# R9A02G021 register map
Vendor: Renesas Electronics Corporation; Series: RISC-V; File version: 1.10.00 + 202304131714_CPU
CPU: other r0p0, little endian, no MPU, no FPU, VTOR, 4 interrupt priority bits, 32 interrupts
Registers are 8-bit, read-write, reset 0x0 unless marked. A register's access mark holds for its fields unless they carry their own. Offsets are from the block's base; [hi:lo] are bit positions; {n}, {i} and the like mark numbered series; <NAME> marks a mode.

## IICA — Serial Interface IICA
Base 0x40093000
{0x0+0x100*i} IICA{i} (i=0..1) — IICA Shift Register {i}
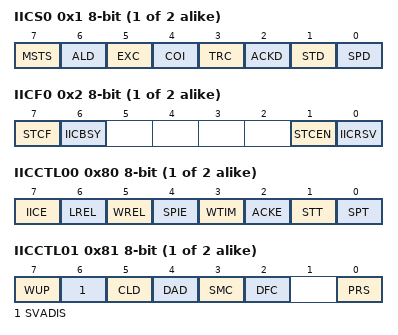
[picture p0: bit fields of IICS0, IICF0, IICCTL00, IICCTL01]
{0x1+0x100*i} IICS{i} (i=0..1) ro — IICA Status Register {i}
  [7] MSTS — Master status check flag
    0=Slave device status or communication standby status; 1=Master device communication status
  [6] ALD — Detection of arbitration loss
    0=This status means either that there was no arbitration, or that the arbitration result was a win; 1=This status indicates the arbitration result was a loss. The MSTS bit is cleared.
  [5] EXC — Detection of extension code reception
    0=Extension code was not received; 1=Extension code was received. Or, the all address match function is enabled.
  [4] COI — Detection of matching addresses
    0=Addresses do not match; 1=Addresses match. Or, the all address match function is enabled.
  [3] TRC — Detection of transmit and receive status
    0=Receive status (other than transmit status). The SDAAn line is set for high impedance.; 1=Transmit status. The value in the SOn latch is enabled for output to the SDAAn line (valid starting at the falling edge of the first byte's ninth clock).
  [2] ACKD — Detection of acknowledge (ACK)
    0=Acknowledge was not detected; 1=Acknowledge was detected
  [1] STD — Detection of start condition
    0=Start condition was not detected; 1=Start condition was detected. This indicates that the address transfer period is in effect.
  [0] SPD — Detection of stop condition
    0=Stop condition was not detected; 1=Stop condition was detected. Communication of the master device is terminated and the bus is released.
{0x2+0x100*i} IICF{i} (i=0..1) — IICA Flag Register {i}
  [7] STCF ro — IICCTLn0.STT clear flag
    0=Generate start condition; 1=Start condition generation unsuccessful: clear the IICCTLn0.STT flag
  [6] IICBSY ro — I2C bus status flag
    0=Bus release status (communication initial status when STCEN = 1); 1=Bus communication status (communication initial status when STCEN = 0)
  [1] STCEN — Initial start enable trigger
    0=After operation is enabled (IICCTLn0.IICE = 1), enable generation of a start condition upon detection of a stop condition; 1=After operation is enabled (IICCTLn0.IICE = 1), enable generation of a start condition without detecting a stop condition
  [0] IICRSV — Communication reservation function disable bit
    0=Enable communication reservation; 1=Disable communication reservation
{0x80+0x100*i} IICCTL{i}0 (i=0..1) — IICA Control Register n0
  [7] IICE — I2C operation enable
    0=Stop operation. Reset the IICA status register n (IICSn). Stop internal operation.; 1=Enable operation
  [6] LREL — Exit from communications
    0=Normal operation; 1=IICA exits from the current communications and sets standby mode. This setting is automatically cleared to 0 after being executed. Its uses include cases in which a locally irrelevant extension code has been received. The SCLAn and SDAAn lines are set to high impedance. The following flags of IICA control register n0 (IICCTLn0) and the IICA status register n (IICSn) are cleared to 0.IICCTLn0.STT, SPTIICSn.MSTS, EXC, COI, TRC, ACKD, STD
  [5] WREL — Release from the clock stretch state
    0=The interface is not released from the clock stretch state; 1=The interface is released from the clock stretch state. After release from the clock stretch state, this bit is automatically cleared to 0.
  [4] SPIE — Enable and disable generation of interrupt request when stop condition is detected
    0=Disable; 1=Enable
  [3] WTIM — Control of clock stretching and interrupt request generation
    0=An interrupt request is generated on the falling edge of the 8th clock cycle. Master mode: After the output of eight clock pulses, the clock output is set to the low level and clock stretching is set. Slave mode: After the input of eight clock pulses, the clock is set to the low level and clock stretching is set for the master device.; 1=An interrupt request is generated on the falling edge of the 9th clock cycle. Master mode: After the output of nine clock pulses, the clock output is set to the low level and clock stretching is set. Slave mode: After the input of 9 clock pulses, the clock is set to the low level and clock stretching is set for the master device.
  [2] ACKE — Acknowledgment control
    0=Disable acknowledgment; 1=Enable acknowledgment. During the 9th clock period, the SDAAn line is set to low level.
  [1] STT — Start condition trigger
    0=Do not generate a start condition; 1=When bus is released (in standby state, when IICFn.IICBSY = 0): If this bit is set to 1, a start condition is generated (startup as the master). When a 3rd-party is communicating: When communication reservation function is enabled (IICFn.IICRSV = 0):This bit functions as the start condition reservation flag. When set to 1, automatically generates a start condition after the bus is released.When communication reservation function is disabled (IICFn.IICRSV = 1):Even if this bit is set to 1, the STT bit is cleared and the STT clear flag (IICFn.STCF) is set to 1. No start condition is generated.In the clock stretch state (for a master device): Generates a restart condition after release from the clock stretch state.
  [0] SPT — Stop condition trigger
    0=Stop condition is not generated; 1=Stop condition is generated (termination of master device transfer)
{0x81+0x100*i} IICCTL{i}1 (i=0..1) — IICA Control Register n1
  [7] WUP — Control of address match wakeup
    0=Stops operation of address match wakeup function in Software Standby mode; 1=Enables operation of address match wakeup function in Software Standby mode
  [6] SVADIS — Address match disabling flag
    0=Disables the all address match function; 1=Enables the all address match function
  [5] CLD ro — Detection of SCLAn pin level (valid only when IICCTLn0.IICE = 1)
    0=The SCLAn pin was detected at low level; 1=The SCLAn pin was detected at high level
  [4] DAD ro — Detection of SDAAn pin level (valid only when IICCTLn0.IICE = 1)
    0=The SDAAn pin was detected at low level; 1=The SDAAn pin was detected at high level
  [3] SMC — Operation mode switching
    0=Operates in standard mode (fastest transfer rate: 100 kbps); 1=Operates in fast mode (fastest transfer rate: 400 kbps) or fast mode plus (fastest transfer rate: 1 Mbps)
  [2] DFC — Digital filter operation control
    0=Digital filter off; 1=Digital filter on
  [0] PRS — IICA operation clock (fMCK)
    0=Selects PCLKB (1 MHz ≤ PCLKB ≤ 20 MHz); 1=Selects PCLKB/2 (20 MHz < PCLKB ≤ 32 MHz)
{0x82+0x100*i} IICWL{i} (i=0..1) reset 0xFF — IICA Low-level Width Setting Register {i}
{0x83+0x100*i} IICWH{i} (i=0..1) reset 0xFF — IICA High-level Width Setting Register {i}
{0x84+0x100*i} SVA{i} (i=0..1) — Slave Address Register {i}
  [7:1] A — 7-bit local address when in slave mode of unit n
